VERSION ""

NS_ :

BS_:

BU_: DAQ M400 PDM

BO_ 3221225472 VECTOR__INDEPENDENT_SIG_MSG: 0 Vector__XXX
 SG_ PDM_counter07 : 0|4@1+ (1,0) [0|0] "" Vector__XXX
 SG_ PDM_counter02 : 0|4@1+ (1,0) [0|15] "" Vector__XXX
 SG_ PDM_counter06 : 0|4@1+ (1,0) [0|0] "" Vector__XXX
 SG_ PDM_counter01 : 0|4@1+ (1,0) [0|15] "" Vector__XXX

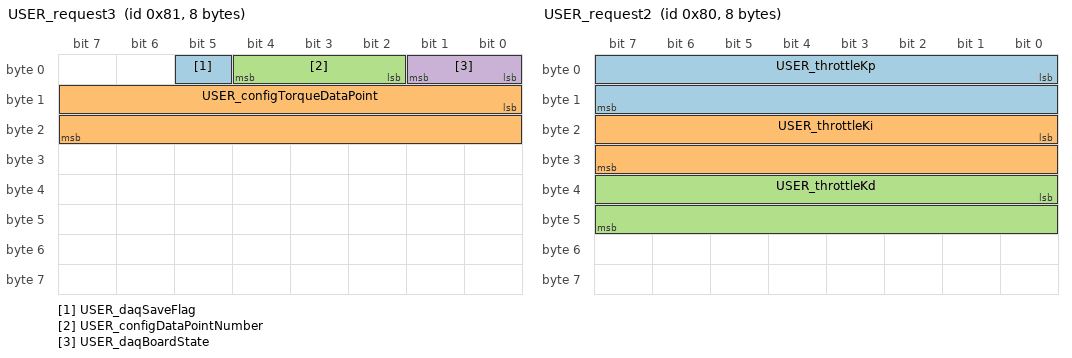
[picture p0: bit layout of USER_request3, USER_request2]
BO_ 129 USER_request3: 8 Vector__XXX
 SG_ USER_daqSaveFlag : 5|1@1+ (1,0) [0|0] "" Vector__XXX
 SG_ USER_configTorqueDataPoint : 8|16@1- (0.1,0) [-3276.8|3276.7] "" Vector__XXX
 SG_ USER_configDataPointNumber : 2|3@1+ (1,0) [0|0] "" Vector__XXX
 SG_ USER_daqBoardState : 0|2@1+ (1,0) [0|0] "" Vector__XXX

BO_ 72 DAQ_00: 8 DAQ
 SG_ DAQ_torqueValue : 0|16@1- (0.1,0) [-3276.8|3276.7] "" Vector__XXX

BO_ 128 USER_request2: 8 Vector__XXX
 SG_ USER_throttleKp : 0|16@1- (0.01,0) [-327.68|327.67] "" Vector__XXX
 SG_ USER_throttleKi : 16|16@1- (0.01,0) [-327.68|327.67] "" Vector__XXX
 SG_ USER_throttleKd : 32|16@1- (0.01,0) [-327.68|327.67] "" Vector__XXX

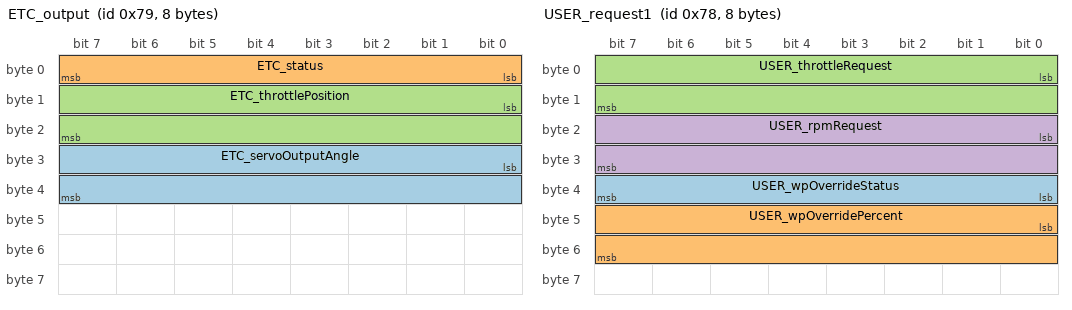
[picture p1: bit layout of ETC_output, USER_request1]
BO_ 121 ETC_output: 8 Vector__XXX
 SG_ ETC_servoOutputAngle : 24|16@1- (1,0) [-32768|32767] "" Vector__XXX
 SG_ ETC_status : 0|8@1- (0.1,0) [0|100] "" Vector__XXX
 SG_ ETC_throttlePosition : 8|16@1- (0.1,0) [-3276.8|3276.7] "" Vector__XXX

BO_ 120 USER_request1: 8 Vector__XXX
 SG_ USER_wpOverrideStatus : 32|8@1- (1,0) [-128|127] "V" Vector__XXX
 SG_ USER_wpOverridePercent : 40|16@1- (1,0) [-32768|32767] "V" Vector__XXX
 SG_ USER_throttleRequest : 0|16@1- (0.1,0) [0|100] "" Vector__XXX
 SG_ USER_rpmRequest : 16|16@1- (0.1,0) [-3276.8|3276.7] "" Vector__XXX

BO_ 1519 M400_dataSet2: 8 M400
 SG_ M400_rowCounterDataSet2 M : 0|8@1+ (1,0) [0|255] "" Vector__XXX
 SG_ M400_oilTemp m18 : 55|16@0- (0.1,0) [-3276.8|3276.7] "" Vector__XXX
 SG_ M400_la1LongTermTrim m18 : 39|16@0- (0.1,0) [-3276.8|3276.7] "" Vector__XXX
 SG_ M400_inletAirTemp m18 : 23|16@0- (0.1,0) [-3276.8|3276.7] "" Vector__XXX
 SG_ M400_ignOut4DutyCycle m17 : 55|16@0- (1,0) [-32768|32767] "" Vector__XXX
 SG_ M400_ignOut3DutyCycle m17 : 39|16@0- (1,0) [-32768|32767] "" Vector__XXX
 SG_ M400_ignOut2DutyCycle m17 : 23|16@0- (1,0) [-32768|32767] "" Vector__XXX
 SG_ M400_ignOut1DutyCycle m16 : 55|16@0- (1,0) [-32768|32767] "" Vector__XXX
 SG_ M400_ignMAPComp m16 : 39|16@0- (0.1,0) [-3276.8|3276.7] "" Vector__XXX
 SG_ M400_ignETComp m16 : 23|16@0- (0.1,0) [-3276.8|3276.7] "" Vector__XXX
 SG_ M400_ignComp2 m15 : 55|16@0- (0.1,0) [-3276.8|3276.7] "" Vector__XXX
 SG_ M400_ignComp1 m15 : 39|16@0- (0.1,0) [-3276.8|3276.7] "" Vector__XXX
 SG_ M400_ignATComp m15 : 23|16@0- (0.1,0) [-3276.8|3276.7] "" Vector__XXX
 SG_ M400_fuelUsed m14 : 55|16@0- (0.01,0) [0|0] "" Vector__XXX
 SG_ M400_fuelTemp m14 : 39|16@0- (0.1,0) [-3276.8|3276.7] "" Vector__XXX
 SG_ M400_fuelStartingComp m14 : 23|16@0- (0.1,0) [-3276.8|3276.7] "" Vector__XXX
 SG_ M400_fuelPressure m13 : 55|16@0- (0.1,0) [-3276.8|3276.7] "" Vector__XXX
 SG_ M400_fuelMAPComp m13 : 39|16@0- (0.1,0) [-3276.8|3276.7] "" Vector__XXX
 SG_ M400_fuelLambdaComp m13 : 23|16@0- (0.1,0) [-3276.8|3276.7] "" Vector__XXX
 SG_ M400_fuelInjDutySec m12 : 55|16@0- (1,0) [-32768|32767] "" Vector__XXX
 SG_ M400_fuelInjDutyPrim m12 : 39|16@0- (1,0) [-32768|32767] "" Vector__XXX
 SG_ M400_fuelInjDutyCycle m12 : 23|16@0- (0.1,0) [0|0] "" Vector__XXX
 SG_ M400_fuelFTComp m11 : 55|16@0- (0.1,0) [-3276.8|3276.7] "" Vector__XXX
 SG_ M400_fuelFPComp m11 : 39|16@0- (0.1,0) [-3276.8|3276.7] "" Vector__XXX
 SG_ M400_fuelETComp m11 : 23|16@0- (0.1,0) [-3276.8|3276.7] "" Vector__XXX
 SG_ M400_fuelDecelClamp m10 : 55|16@0- (1,0) [-32768|32767] "" Vector__XXX
 SG_ M400_fuelDecel m10 : 39|16@0- (1,0) [-32768|32767] "" Vector__XXX
 SG_ M400_fuelComp2 m10 : 23|16@0- (0.1,0) [0|0] "" Vector__XXX
 SG_ M400_fuelComp1 m9 : 55|16@0- (0.1,0) [0|0] "" Vector__XXX
 SG_ M400_fuelBasePulseW m9 : 39|16@0- (0.002,0) [-65.536|65.534] "" Vector__XXX
 SG_ M400_fuelATComp m9 : 23|16@0- (0.1,0) [-3276.8|3276.7] "" Vector__XXX
 SG_ M400_fuelActualPulseW m8 : 55|16@0- (0.002,0) [0|0] "" Vector__XXX
 SG_ M400_fuelAccelClamp m8 : 39|16@0- (0.002,0) [0|0] "" Vector__XXX
 SG_ M400_fuelAccel m8 : 23|16@0- (1,0) [-32768|32767] "" Vector__XXX
 SG_ M400_fuel4PulseWidth m7 : 55|16@0- (0.002,0) [0|0] "" Vector__XXX
 SG_ M400_fuel4IndivTrim m7 : 39|16@0- (1,0) [-32768|32767] "" Vector__XXX
 SG_ M400_fuel3PulseWidth m7 : 23|16@0- (0.002,0) [0|0] "" Vector__XXX
 SG_ M400_fuel3IndivTrim m6 : 55|16@0- (1,0) [-32768|32767] "" Vector__XXX
 SG_ M400_fuel2PulseWidth m6 : 39|16@0- (0.002,0) [0|0] "" Vector__XXX
 SG_ M400_fuel2IndivTrim m6 : 23|16@0- (1,0) [-32768|32767] "" Vector__XXX
 SG_ M400_fuel1PulseWidth m5 : 55|16@0- (0.002,0) [0|0] "" Vector__XXX
 SG_ M400_fuel1IndivTrim m5 : 39|16@0- (1,0) [-32768|32767] "" Vector__XXX
 SG_ M400_exhaustGasTemp4 m5 : 23|16@0- (1,0) [-32768|32767] "" Vector__XXX
 SG_ M400_exhaustGasTemp3 m4 : 55|16@0- (1,0) [-32768|32767] "" Vector__XXX
 SG_ M400_exhaustGasTemp2 m4 : 39|16@0- (1,0) [-32768|32767] "" Vector__XXX
 SG_ M400_exhaustGasTemp1 m4 : 23|16@0- (1,0) [-32768|32767] "" Vector__XXX
 SG_ M400_engineTemp m3 : 55|16@0- (0.1,0) [-3276.8|3276.7] "" Vector__XXX
 SG_ M400_ecuInternalTemp m3 : 39|16@0- (0.1,0) [-3276.8|3276.7] "" Vector__XXX
 SG_ M400_ecuCPUusage m3 : 23|16@0- (0.1,0) [0|0] "" Vector__XXX
 SG_ M400_batteryVoltage m2 : 55|16@0- (0.01,0) [-327.68|327.67] "" Vector__XXX
 SG_ M400_auxOut8DutyCycle m2 : 39|16@0- (1,0) [-32768|32767] "" Vector__XXX
 SG_ M400_auxOut7DutyCycle m2 : 23|16@0- (1,0) [-32768|32767] "" Vector__XXX
 SG_ M400_auxOut6DutyCycle m1 : 55|16@0- (1,0) [-32768|32767] "" Vector__XXX
 SG_ M400_auxOut5DutyCycle m1 : 39|16@0- (1,0) [-32768|32767] "" Vector__XXX
 SG_ M400_auxOut4DutyCycle m1 : 23|16@0- (1,0) [-32768|32767] "" Vector__XXX
 SG_ M400_auxOut3DutyCycle m0 : 55|16@0- (1,0) [-32768|32767] "" Vector__XXX
 SG_ M400_auxOut2DutyCycle m0 : 39|16@0- (1,0) [-32768|32767] "" Vector__XXX
 SG_ M400_auxOut1DutyCycle m0 : 23|16@0- (1,0) [-32768|32767] "" Vector__XXX

BO_ 1520 M400_dataSet1: 8 M400
 SG_ M400_throttlePosition m10 : 23|16@0- (0.1,0) [-3276.8|3276.7] "" Vector__XXX
 SG_ M400_rpm m9 : 55|16@0- (1,0) [-32768|32767] "" Vector__XXX
 SG_ M400_oilPressure m9 : 39|16@0- (0.1,0) [-3276.8|3276.7] "" Vector__XXX
 SG_ M400_manifoldPressure m9 : 23|16@0- (0.1,0) [-3276.8|3276.7] "" Vector__XXX
 SG_ M400_lambda1 m8 : 55|16@0- (0.001,0) [-32.768|32.767] "" Vector__XXX
 SG_ M400_la1ShortTermTrim m8 : 39|16@0- (0.1,0) [-3276.8|3276.7] "" Vector__XXX
 SG_ M400_la1AimValue m8 : 23|16@0- (0.001,0) [-32.768|32.767] "" Vector__XXX
 SG_ M400_knock1 m7 : 55|16@0- (1,0) [-32768|32767] "" Vector__XXX
 SG_ M400_ignOverallTrim m6 : 23|16@0- (0.1,0) [-3276.8|3276.7] "" Vector__XXX
 SG_ M400_ignDwellTime m7 : 39|16@0- (0.002,0) [-65.536|65.534] "" Vector__XXX
 SG_ M400_ignDecel m7 : 23|16@0- (1,0) [-32768|32767] "" Vector__XXX
 SG_ M400_ignCutLevelTotal m5 : 55|16@0- (1,0) [-32768|32767] "" Vector__XXX
 SG_ M400_ignBaseAdvance m5 : 39|16@0- (0.1,0) [-3276.8|3276.7] "" Vector__XXX
 SG_ M400_ignAdvance m6 : 55|16@0- (0.1,0) [-3276.8|3276.7] "" Vector__XXX
 SG_ M400_ignAccel m6 : 39|16@0- (1,0) [-32768|32767] "" Vector__XXX
 SG_ M400_ign4IndivTrim m5 : 23|16@0- (0.2,0) [-6553.6|6553.4] "" Vector__XXX
 SG_ M400_ign4Advance m4 : 55|16@0- (0.1,0) [-3276.8|3276.7] "" Vector__XXX
 SG_ M400_ign3IndivTrim m4 : 39|16@0- (0.2,0) [-6553.6|6553.4] "" Vector__XXX
 SG_ M400_ign3Advance m4 : 23|16@0- (0.1,0) [-3276.8|3276.7] "" Vector__XXX
 SG_ M400_ign2IndivTrim m3 : 55|16@0- (0.2,0) [-6553.6|6553.4] "" Vector__XXX
 SG_ M400_ign2Advance m3 : 39|16@0- (0.1,0) [-3276.8|3276.7] "" Vector__XXX
 SG_ M400_ign1IndivTrim m3 : 23|16@0- (0.2,0) [-6553.6|6553.4] "" Vector__XXX
 SG_ M400_ign1Advance m2 : 55|16@0- (0.1,0) [-3276.8|3276.7] "" Vector__XXX
 SG_ M400_gearSensorVoltage m2 : 39|16@0- (0.001,0) [-32.768|32.767] "" Vector__XXX
 SG_ M400_gearDet m2 : 23|16@0- (1,0) [-32768|32767] "" Vector__XXX
 SG_ M400_gear m1 : 55|16@0- (1,0) [-32768|32767] "" Vector__XXX
 SG_ M400_fuelOverallTrim m1 : 39|16@0- (0.1,0) [0|0] "" Vector__XXX
 SG_ M400_fuelInjTimingSec m1 : 23|16@0- (0.1,0) [-3276.8|3276.7] "" Vector__XXX
 SG_ M400_fuelInjTimingComp m0 : 55|16@0- (1,0) [-32768|32767] "" Vector__XXX
 SG_ M400_fuelInjTiming m0 : 39|16@0- (0.1,0) [-3276.8|3276.7] "" Vector__XXX
 SG_ M400_fuelCutLevelTotal m0 : 23|16@0- (0.1,0) [-3276.8|3276.7] "" Vector__XXX
 SG_ M400_rowCounterDataSet1 M : 0|8@1+ (1,0) [0|255] "" Vector__XXX

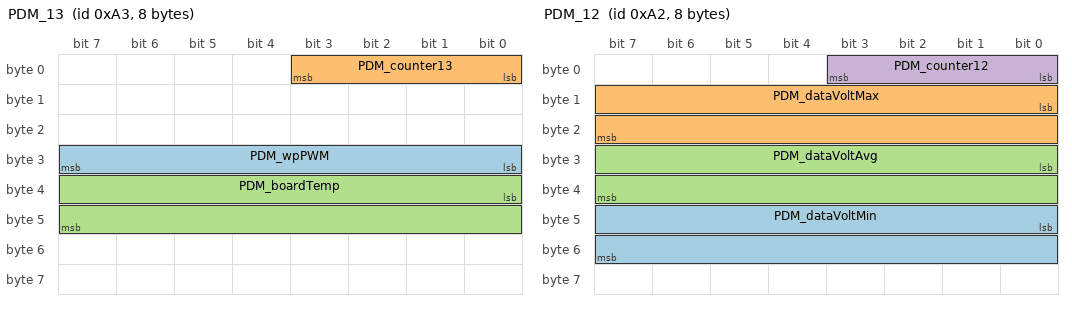
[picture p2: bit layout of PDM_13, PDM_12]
BO_ 163 PDM_13: 8 PDM
 SG_ PDM_wpPWM : 24|8@1+ (1,0) [0|255] "" Vector__XXX
 SG_ PDM_counter13 : 0|4@1+ (1,0) [0|0] "" Vector__XXX
 SG_ PDM_boardTemp : 32|16@1- (0.1,0) [-3276.8|3276.7] "C" Vector__XXX

BO_ 162 PDM_12: 8 PDM
 SG_ PDM_dataVoltMin : 40|16@1- (0.001,0) [-32.768|32.767] "V" Vector__XXX
 SG_ PDM_dataVoltMax : 8|16@1- (0.001,0) [-32.768|32.767] "V" Vector__XXX
 SG_ PDM_dataVoltAvg : 24|16@1- (0.001,0) [-32.768|32.767] "V" Vector__XXX
 SG_ PDM_counter12 : 0|4@1+ (1,0) [0|0] "" Vector__XXX

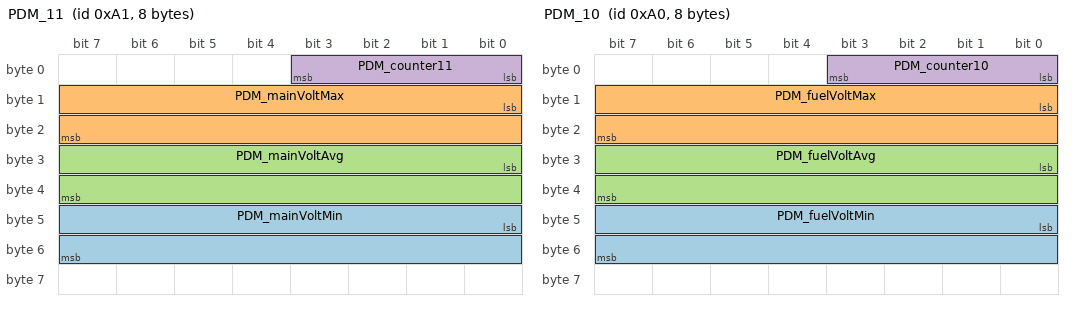
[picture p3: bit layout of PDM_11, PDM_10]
BO_ 161 PDM_11: 8 PDM
 SG_ PDM_mainVoltMin : 40|16@1- (0.001,0) [-32.768|32.767] "V" Vector__XXX
 SG_ PDM_mainVoltMax : 8|16@1- (0.001,0) [-32.768|32.767] "V" Vector__XXX
 SG_ PDM_mainVoltAvg : 24|16@1- (0.001,0) [-32.768|32.767] "V" Vector__XXX
 SG_ PDM_counter11 : 0|4@1+ (1,0) [0|0] "" Vector__XXX

BO_ 160 PDM_10: 8 PDM
 SG_ PDM_fuelVoltMin : 40|16@1- (0.001,0) [-32.768|32.767] "V" Vector__XXX
 SG_ PDM_fuelVoltMax : 8|16@1- (0.001,0) [-32.768|32.767] "V" Vector__XXX
 SG_ PDM_fuelVoltAvg : 24|16@1- (0.001,0) [-32.768|32.767] "V" Vector__XXX
 SG_ PDM_counter10 : 0|4@1+ (1,0) [0|0] "" Vector__XXX

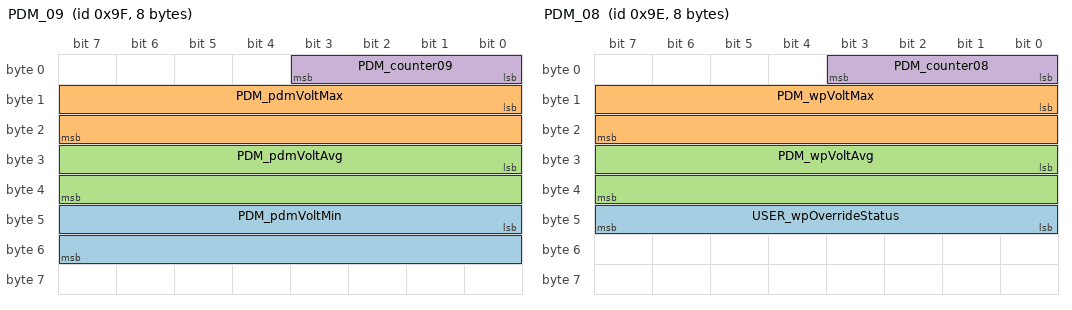
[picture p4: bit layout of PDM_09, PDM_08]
BO_ 159 PDM_09: 8 PDM
 SG_ PDM_pdmVoltMin : 40|16@1- (0.001,0) [-32.768|32.767] "V" Vector__XXX
 SG_ PDM_pdmVoltMax : 8|16@1- (0.001,0) [-32.768|32.767] "V" Vector__XXX
 SG_ PDM_pdmVoltAvg : 24|16@1- (0.001,0) [-32.768|32.767] "V" Vector__XXX
 SG_ PDM_counter09 : 0|4@1+ (1,0) [0|0] "" Vector__XXX

BO_ 158 PDM_08: 8 PDM
 SG_ USER_wpOverrideStatus : 40|8@1- (1,0) [-128|127] "V" Vector__XXX
 SG_ PDM_wpVoltMax : 8|16@1- (0.001,0) [-32.768|32.767] "V" Vector__XXX
 SG_ PDM_wpVoltAvg : 24|16@1- (0.001,0) [-32.768|32.767] "V" Vector__XXX
 SG_ PDM_counter08 : 0|4@1+ (1,0) [0|0] "" Vector__XXX

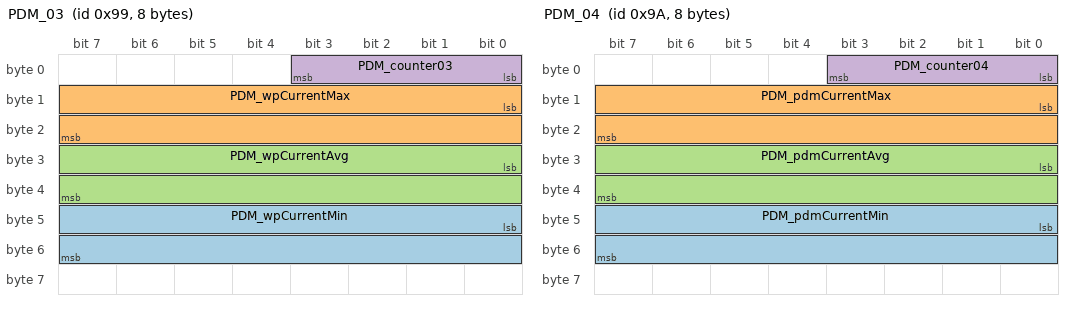
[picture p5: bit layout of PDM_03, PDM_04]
BO_ 153 PDM_03: 8 PDM
 SG_ PDM_wpCurrentMin : 40|16@1- (0.01,0) [-327.68|327.67] "A" Vector__XXX
 SG_ PDM_wpCurrentMax : 8|16@1- (0.01,0) [-327.68|327.67] "A" Vector__XXX
 SG_ PDM_wpCurrentAvg : 24|16@1- (0.01,0) [-327.68|327.67] "A" Vector__XXX
 SG_ PDM_counter03 : 0|4@1+ (1,0) [0|15] "" Vector__XXX

BO_ 154 PDM_04: 8 PDM
 SG_ PDM_pdmCurrentMin : 40|16@1- (0.01,0) [-327.68|327.67] "A" Vector__XXX
 SG_ PDM_pdmCurrentMax : 8|16@1- (0.01,0) [-327.68|327.67] "A" Vector__XXX
 SG_ PDM_pdmCurrentAvg : 24|16@1- (0.01,0) [-327.68|327.67] "A" Vector__XXX
 SG_ PDM_counter04 : 0|4@1+ (1,0) [0|0] "" Vector__XXX

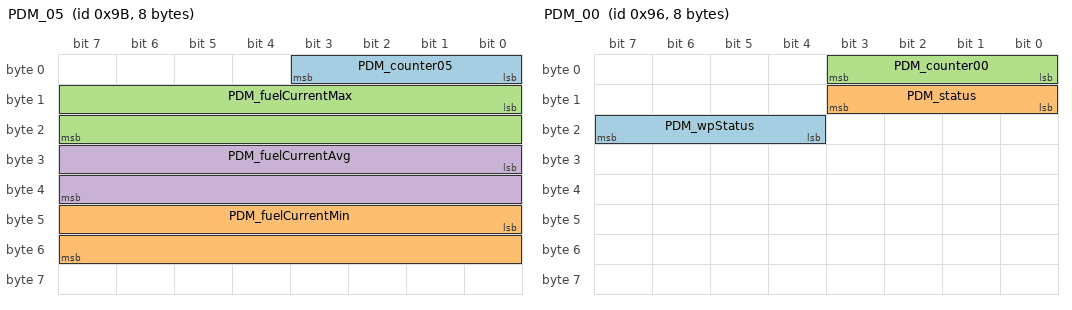
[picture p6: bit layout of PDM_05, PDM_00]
BO_ 155 PDM_05: 8 PDM
 SG_ PDM_counter05 : 0|4@1+ (1,0) [0|0] "" Vector__XXX
 SG_ PDM_fuelCurrentMin : 40|16@1- (0.01,0) [-327.68|327.67] "A" Vector__XXX
 SG_ PDM_fuelCurrentMax : 8|16@1- (0.01,0) [-327.68|327.67] "A" Vector__XXX
 SG_ PDM_fuelCurrentAvg : 24|16@1- (0.01,0) [-327.68|327.67] "A" Vector__XXX

BO_ 150 PDM_00: 8 PDM
 SG_ PDM_wpStatus : 20|4@1+ (1,0) [0|15] "" Vector__XXX
 SG_ PDM_status : 8|4@1+ (1,0) [0|15] "" Vector__XXX
 SG_ PDM_counter00 : 0|4@1+ (1,0) [0|15] "" Vector__XXX

CM_ BU_ PDM "Power Distrubution Module";
CM_ BO_ 3221225472 "This is a message for not used signals, created by Vector CANdb++ DBC OLE DB Provider.";
CM_ SG_ 129 USER_daqSaveFlag "Signal for Saving Config to EEPROM
";
CM_ SG_ 129 USER_configTorqueDataPoint "Torque from Computer for Doing Configuration";
CM_ SG_ 129 USER_configDataPointNumber "Selecting Which Data Point is Being Configured";
CM_ SG_ 129 USER_daqBoardState "Board State for Configuration";
CM_ SG_ 72 DAQ_torqueValue "Torque Value from Board
";
CM_ SG_ 128 USER_throttleKp "etc PID";
CM_ SG_ 128 USER_throttleKi "etc PID";
CM_ SG_ 128 USER_throttleKd "etc PID";
CM_ SG_ 121 ETC_servoOutputAngle "throttle output from the ETC module";
CM_ SG_ 121 ETC_status "-1= unknown error;
0 = idle;
1 = throttle position request;
2 = rpm override request;
3 = signal timed-out;";
CM_ SG_ 121 ETC_throttlePosition "throttle output from the ETC module";
CM_ SG_ 120 USER_wpOverrideStatus "the voltage of the water pump";
CM_ SG_ 120 USER_wpOverridePercent "the voltage of the water pump";
CM_ SG_ 120 USER_throttleRequest "throttle request sent to ETC module";
CM_ SG_ 120 USER_rpmRequest "rpm request sent to ETC module";
CM_ SG_ 163 PDM_wpPWM "The PWM rate of the waterpump";
CM_ SG_ 163 PDM_boardTemp "PDM board temperature";
CM_ SG_ 162 PDM_dataVoltMin "voltage of the data circuit";
CM_ SG_ 162 PDM_dataVoltMax "voltage of the data circuit";
CM_ SG_ 162 PDM_dataVoltAvg "voltage of the data circuit";
CM_ SG_ 161 PDM_mainVoltMin "voltage of the main circuit";
CM_ SG_ 161 PDM_mainVoltMax "voltage of the main circuit";
CM_ SG_ 161 PDM_mainVoltAvg "voltage of the main circuit";
CM_ SG_ 160 PDM_fuelVoltMin "voltage of the fuel circuit";
CM_ SG_ 160 PDM_fuelVoltMax "voltage of the fuel circuit";
CM_ SG_ 160 PDM_fuelVoltAvg "voltage of the fuel circuit";
CM_ SG_ 159 PDM_pdmVoltMin "voltage of the PDM";
CM_ SG_ 159 PDM_pdmVoltMax "voltage of the PDM";
CM_ SG_ 159 PDM_pdmVoltAvg "voltage of the PDM";
CM_ SG_ 158 USER_wpOverrideStatus "the voltage of the water pump";
CM_ SG_ 158 PDM_wpVoltMax "the voltage of the water pump";
CM_ SG_ 158 PDM_wpVoltAvg "the voltage of the water pump";
CM_ SG_ 153 PDM_wpCurrentMin "the current going through the water pump";
CM_ SG_ 153 PDM_wpCurrentMax "the current going through the water pump";
CM_ SG_ 153 PDM_wpCurrentAvg "the current going through the water pump";
CM_ SG_ 154 PDM_pdmCurrentMin "the total current going through the PDM";
CM_ SG_ 154 PDM_pdmCurrentMax "the total current going through the PDM";
CM_ SG_ 154 PDM_pdmCurrentAvg "the total current going through the PDM";
CM_ SG_ 155 PDM_fuelCurrentMin "current through the fuel circuit";
CM_ SG_ 155 PDM_fuelCurrentMax "current through the fuel circuit";
CM_ SG_ 155 PDM_fuelCurrentAvg "current through the fuel circuit";
CM_ SG_ 150 PDM_wpStatus "status of the water pump";
CM_ SG_ 150 PDM_status "to be used to print error messages:

0 =
1 =
2 =
3 =
4 =
5 =
6 =
7 =
8 =
9 =
10 =
11 =
12 =
13 =
14 =
15 =  ";
BA_DEF_  "BusType" STRING ;
BA_DEF_DEF_  "BusType" "CAN";
